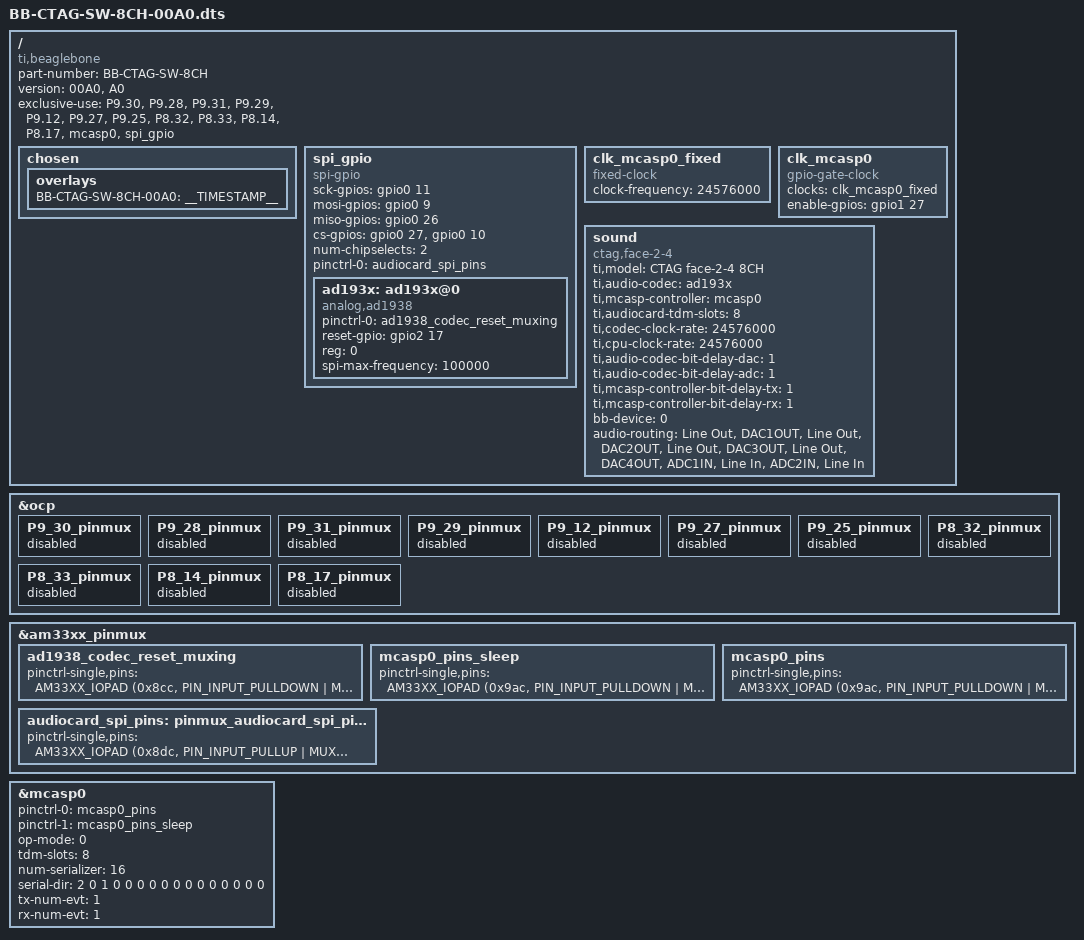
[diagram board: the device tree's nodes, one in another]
/*
 * Device Tree Overlay for CTAG face2|4 multichannel soundcard - 8 audio channels
 *
 * Author: Henrik Langer <henni19790@googlemail.com>
 *
 * This program is free software; you can redistribute it and/or modify
 * it under the terms of the GNU General Public License version 3 as
 * published by the Free Software Foundation.
 */
/dts-v1/;
/plugin/;

#include <dt-bindings/board/am335x-bbw-bbb-base.h>
#include <dt-bindings/gpio/gpio.h>
#include <dt-bindings/pinctrl/am33xx.h>

/ {
	compatible = "ti,beaglebone", "ti,beaglebone-black", "ti,beaglebone-green";

	/* identification */
	part-number = "BB-CTAG-SW-8CH";
	version = "00A0", "A0";

	/* state the resources this cape uses */
	exclusive-use =
		/* audio */
		"P9.30",	/* mcasp0_axr0 		audio in */
		"P9.28",	/* mcasp0_axr2 		audio out */
		"P9.31",	/* mcasp0_ahclkx	transmit bitclock */
		"P9.29",	/* mcasp0_fsx 		transmit frameclock */
		"P9.12",	/* mcasp0_aclkr		receive bitclock */
		"P9.27",	/* mcasp0_fsr		receive frameclock */
		"P9.25",	/* mcasp0_ahclkx 	masterclock */
		/* spi */
		"P8.32",	/* spi_sclk */
		"P8.33",	/* spi_mosi */
		"P8.14",	/* spi_miso */
		"P8.17",	/* spi_cs0 */
		/* the hardware ip uses */
		"mcasp0", "spi_gpio";

	fragment@0 {
		target-path = "/";
		__overlay__ {
			chosen {
				overlays {
					BB-CTAG-SW-8CH-00A0 = __TIMESTAMP__;
				};
			};
		};
	};

	/*
	 * Free up the pins used by the cape from the pinmux helpers.
	 */
	fragment@1 {
		target = <&ocp>;
		__overlay__ {
			P9_30_pinmux { status = "disabled"; };	/* mcasp0_axr0 		audio in */
			P9_28_pinmux { status = "disabled"; };	/* mcasp0_axr2 		audio out */
			P9_31_pinmux { status = "disabled"; };	/* mcasp0_ahclkx	transmit bitclock */
			P9_29_pinmux { status = "disabled"; };	/* mcasp0_fsx 		transmit frameclock */
			P9_12_pinmux { status = "disabled"; };	/* mcasp0_aclkr		receive bitclock */
			P9_27_pinmux { status = "disabled"; };	/* mcasp0_fsr		receive frameclock */
			P9_25_pinmux { status = "disabled"; };	/* mcasp0_ahclkx 	masterclock */
			P8_32_pinmux { status = "disabled"; };	/* spi_sclk */
			P8_33_pinmux { status = "disabled"; };	/* spi_mosi */
			P8_14_pinmux { status = "disabled"; };	/* spi_miso */
			P8_17_pinmux { status = "disabled"; };	/* spi_cs0 */
		};
	};
	
	fragment@2 {
		target-path = "/";
		__overlay__ {
			spi_gpio: spi_gpio {
				compatible = "spi-gpio";
				#address-cells = <1>;
				#size-cells = <0>;

				sck-gpios = <&gpio0 11 0>; //P8.32
				mosi-gpios = <&gpio0 9 0>; //P8.33
				miso-gpios = <&gpio0 26 0>; //P8.14
				cs-gpios = <&gpio0 27 0 &gpio0 10 0>; //P8.17 / P8.31
				num-chipselects = <2>;

				pinctrl-names = "default";
				/* avoid dtc warnings */
				pinctrl-0 = <&audiocard_spi_pins>;
				status = "okay";

				ad193x: ad193x@0{
					pinctrl-names = "default";
					pinctrl-0 = <&ad1938_codec_reset_muxing>;
					#address-cells = <1>;
					#size-cells = <0>;

					compatible = "analog,ad1938";
					status = "okay";
					reset-gpio = <&gpio2 17 0>;
					reg = <0>; //corresponds to cs
					spi-max-frequency = <100000>;
				};
			};
		};
	};

	fragment@3 {
		target = <&am33xx_pinmux>;
		__overlay__ {
			ad1938_codec_reset_muxing: ad1938_codec_reset_muxing {
				pinctrl-single,pins = <
					AM33XX_IOPAD (0x8cc, PIN_INPUT_PULLDOWN | MUX_MODE7)      /*  MODE7 | RESET P8.34 */
				>;
			};

			mcasp0_pins_sleep: mcasp0_pins_sleep {
				pinctrl-single,pins = <
					AM33XX_IOPAD (0x9ac, PIN_INPUT_PULLDOWN | MUX_MODE7)	/* mcasp0_ahclkx */
					AM33XX_IOPAD (0x99c, PIN_INPUT_PULLDOWN | MUX_MODE7)	/* mcasp0_axr2 */
					AM33XX_IOPAD (0x994, PIN_INPUT_PULLDOWN | MUX_MODE7)	/* mcasp0_fsx */
					AM33XX_IOPAD (0x990, PIN_INPUT_PULLDOWN | MUX_MODE7)	/* mcasp0_aclkx */
					AM33XX_IOPAD (0x9a4, PIN_INPUT_PULLDOWN | MUX_MODE0)	/* mcasp0_fsr */
					AM33XX_IOPAD (0x878, PIN_INPUT_PULLDOWN | MUX_MODE6)	/* mcasp0_aclkr */
					AM33XX_IOPAD (0x998, PIN_INPUT_PULLDOWN | MUX_MODE7)	/* mcasp0_axr0 */
					0x06c (PIN_INPUT_PULLDOWN | MUX_MODE7)	/* gpio1[27] */
				>;
			};

			mcasp0_pins: mcasp0_pins {
				pinctrl-single,pins = <
					AM33XX_IOPAD (0x9ac, PIN_INPUT_PULLDOWN | MUX_MODE0)	/* mcasp0_ahclkx */
					AM33XX_IOPAD (0x99c, PIN_OUTPUT_PULLDOWN | MUX_MODE2) /* mcasp0_axr2 */
					AM33XX_IOPAD (0x994, PIN_INPUT_PULLDOWN | MUX_MODE0)	/* mcasp0_fsx */
					AM33XX_IOPAD (0x990, PIN_INPUT_PULLDOWN | MUX_MODE0)	/* mcasp0_aclkx */
					AM33XX_IOPAD (0x9a4, PIN_INPUT_PULLDOWN | MUX_MODE0)	/* mcasp0_fsr */
					AM33XX_IOPAD (0x878, PIN_INPUT_PULLDOWN | MUX_MODE6)	/* mcasp0_aclkr */
					AM33XX_IOPAD (0x998, PIN_INPUT_PULLDOWN | MUX_MODE0)	/* mcasp0_axr0 */
					0x06c (PIN_OUTPUT_PULLDOWN | MUX_MODE7)	/* gpio1[27] (enable oscillator) */
				>;
			};

			audiocard_spi_pins: pinmux_audiocard_spi_pins { 
				pinctrl-single,pins = <
					AM33XX_IOPAD (0x8dc, PIN_INPUT_PULLUP | MUX_MODE7)	  /* spi_sclk, 	MODE7 | INPUT_PULLUP | SPI_SCLK P8_32 */
					AM33XX_IOPAD (0x828, PIN_INPUT_PULLUP | MUX_MODE7)	  /* spi_miso, 	MODE7 | INPUT_PULLUP | SPI_MISO P8_14 */
					AM33XX_IOPAD (0x8d4, PIN_OUTPUT_PULLUP | MUX_MODE7)  /* spi_mosi, 	MODE7 | OUTPUT_PULLUP | SPI_MOSI P8_33 */
					AM33XX_IOPAD (0x82c, PIN_OUTPUT_PULLUP | MUX_MODE7)  /* spi_cs0, 	MODE7 | OUTPUT_PULLUP | SPI_CS0 P8_17 */
				>;
			};
		};
	};

	fragment@4 {
		target = <&mcasp0>;
		__overlay__ {
			pinctrl-names = "default", "sleep";
			pinctrl-0 = <&mcasp0_pins>;
			pinctrl-1 = <&mcasp0_pins_sleep>;
			status = "okay";
			op-mode = <0>;	/* MCASP_IIS_MODE */
			tdm-slots = <8>;
			num-serializer = <16>;
			serial-dir = <	/* 0: INACTIVE, 1: TX, 2: RX */
				2 0 1 0
				0 0 0 0
				0 0 0 0
				0 0 0 0
			>;
			tx-num-evt = <1>;
			rx-num-evt = <1>;
		};
	};

	fragment@5 {
		target-path = "/";
		__overlay__ {

			clk_mcasp0_fixed: clk_mcasp0_fixed {
				#clock-cells = <0>;
				compatible = "fixed-clock";
				clock-frequency = <24576000>;
			};

			clk_mcasp0: clk_mcasp0 {
				#clock-cells = <0>;
				compatible = "gpio-gate-clock";
				clocks = <&clk_mcasp0_fixed>;
				enable-gpios = <&gpio1 27 GPIO_ACTIVE_HIGH>; /* BeagleBone Black Clk enable on GPIO1_27 */
			};

			sound {
				compatible = "ctag,face-2-4";
				ti,model = "CTAG face-2-4 8CH";
				ti,audio-codec = <&ad193x>;
				ti,mcasp-controller = <&mcasp0>;
				ti,audiocard-tdm-slots = <8>;
				ti,codec-clock-rate = <24576000>;
				ti,cpu-clock-rate = <24576000>;
				status = "okay";
				
				ti,audio-codec-bit-delay-dac = <1>; //currently only supports 1 or 0 bit delay
				ti,audio-codec-bit-delay-adc = <1>;
				ti,mcasp-controller-bit-delay-tx = <1>;
				ti,mcasp-controller-bit-delay-rx = <1>;
				bb-device = <0>; //BBB
				audio-routing =
					"Line Out",             "DAC1OUT",
					"Line Out",             "DAC2OUT",
					"Line Out",             "DAC3OUT",
					"Line Out",             "DAC4OUT",
					"ADC1IN",               "Line In",
					"ADC2IN",               "Line In";
			};
		};
	};
};
